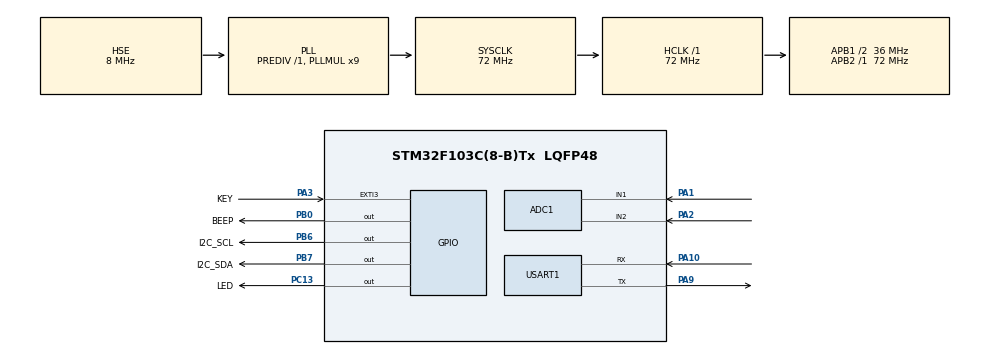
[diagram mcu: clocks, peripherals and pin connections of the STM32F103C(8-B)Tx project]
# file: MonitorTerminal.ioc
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ADC1.Channel-4\#ChannelRegularConversion=ADC_CHANNEL_1
ADC1.Channel-5\#ChannelRegularConversion=ADC_CHANNEL_2
ADC1.ContinuousConvMode=ENABLE
ADC1.DataAlign=ADC_DATAALIGN_RIGHT
ADC1.DiscontinuousConvMode=DISABLE
ADC1.NbrOfConversion=2
ADC1.NbrOfConversionFlag=1
ADC1.Rank-4\#ChannelRegularConversion=1
ADC1.Rank-5\#ChannelRegularConversion=2
ADC1.SamplingTime-4\#ChannelRegularConversion=ADC_SAMPLETIME_55CYCLES_5
ADC1.SamplingTime-5\#ChannelRegularConversion=ADC_SAMPLETIME_55CYCLES_5
ADC1.master=1
Dma.ADC1.1.Direction=DMA_PERIPH_TO_MEMORY
Dma.ADC1.1.Instance=DMA1_Channel1
Dma.ADC1.1.MemDataAlignment=DMA_MDATAALIGN_HALFWORD
Dma.ADC1.1.MemInc=DMA_MINC_ENABLE
Dma.ADC1.1.Mode=DMA_CIRCULAR
Dma.ADC1.1.PeriphDataAlignment=DMA_PDATAALIGN_HALFWORD
Dma.ADC1.1.PeriphInc=DMA_PINC_DISABLE
Dma.ADC1.1.Priority=DMA_PRIORITY_LOW
Dma.Request0=USART1_TX
Dma.Request1=ADC1
Dma.USART1_TX.0.Direction=DMA_MEMORY_TO_PERIPH
Dma.USART1_TX.0.Instance=DMA1_Channel4
Dma.USART1_TX.0.MemDataAlignment=DMA_MDATAALIGN_BYTE
Dma.USART1_TX.0.MemInc=DMA_MINC_ENABLE
Dma.USART1_TX.0.Mode=DMA_NORMAL
Dma.USART1_TX.0.PeriphDataAlignment=DMA_PDATAALIGN_BYTE
Dma.USART1_TX.0.PeriphInc=DMA_PINC_DISABLE
Dma.USART1_TX.0.Priority=DMA_PRIORITY_LOW
FREERTOS.configTOTAL_HEAP_SIZE=10240
IWDG.Prescaler=IWDG_PRESCALER_64
IWDG.Reload=1249
Mcu.Family=STM32F1
Mcu.Name=STM32F103C(8-B)Tx
Mcu.Package=LQFP48
NVIC.DMA1_Channel1_IRQn=true\:5\:0\:true\:false\:true\:true\:false\:true\:true
NVIC.DMA1_Channel4_IRQn=true\:5\:0\:true\:false\:true\:true\:false\:true\:true
NVIC.EXTI3_IRQn=true\:5\:0\:true\:false\:true\:true\:false\:true\:true
NVIC.PriorityGroup=NVIC_PRIORITYGROUP_4
NVIC.TIM4_IRQn=true\:0\:0\:false\:false\:true\:false\:false\:true\:true
NVIC.TimeBase=TIM4_IRQn
NVIC.TimeBaseIP=TIM4
NVIC.USART1_IRQn=true\:5\:0\:true\:false\:true\:true\:false\:true\:true
PA1.Signal=ADCx_IN1
PA10.Mode=Asynchronous
PA10.Signal=USART1_RX
PA13.Mode=Serial_Wire
PA13.Signal=SYS_JTMS-SWDIO
PA14.Mode=Serial_Wire
PA14.Signal=SYS_JTCK-SWCLK
PA2.Signal=ADCx_IN2
PA3.GPIO_Label=KEY
PA3.GPIO_ModeDefaultEXTI=GPIO_MODE_IT_FALLING
PA3.GPIO_PuPd=GPIO_PULLUP
PA3.Signal=GPXTI3
PA9.Mode=Asynchronous
PA9.Signal=USART1_TX
PB0.GPIO_Label=BEEP
PB0.Signal=GPIO_Output
PB6.GPIO_Label=I2C_SCL
PB6.GPIO_ModeDefaultOutputPP=GPIO_MODE_OUTPUT_OD
PB6.GPIO_PuPd=GPIO_PULLUP
PB6.GPIO_Speed=GPIO_SPEED_FREQ_HIGH
PB6.PinState=GPIO_PIN_SET
PB6.Signal=GPIO_Output
PB7.GPIO_Label=I2C_SDA
PB7.GPIO_ModeDefaultOutputPP=GPIO_MODE_OUTPUT_OD
PB7.GPIO_PuPd=GPIO_PULLUP
PB7.GPIO_Speed=GPIO_SPEED_FREQ_HIGH
PB7.PinState=GPIO_PIN_SET
PB7.Signal=GPIO_Output
PC13-TAMPER-RTC.GPIO_Label=LED
PC13-TAMPER-RTC.PinState=GPIO_PIN_SET
PC13-TAMPER-RTC.Signal=GPIO_Output
PD0-OSC_IN.Mode=HSE-External-Oscillator
PD0-OSC_IN.Signal=RCC_OSC_IN
PD1-OSC_OUT.Mode=HSE-External-Oscillator
PD1-OSC_OUT.Signal=RCC_OSC_OUT
ProjectManager.HeapSize=0x200
ProjectManager.StackSize=0x400
ProjectManager.TargetToolchain=MDK-ARM V5
RCC.ADCPresc=RCC_ADCPCLK2_DIV6
RCC.AHBFreq_Value=72000000
RCC.APB1CLKDivider=RCC_HCLK_DIV2
RCC.APB1Freq_Value=36000000
RCC.APB1TimFreq_Value=72000000
RCC.APB2Freq_Value=72000000
RCC.APB2TimFreq_Value=72000000
RCC.HCLKFreq_Value=72000000
RCC.PLLMUL=RCC_PLL_MUL9
RCC.PLLSourceVirtual=RCC_PLLSOURCE_HSE
RCC.SYSCLKFreq_VALUE=72000000
RCC.SYSCLKSource=RCC_SYSCLKSOURCE_PLLCLK
RCC.USBFreq_Value=72000000
SH.ADCx_IN1.0=ADC1_IN1,IN1
SH.ADCx_IN2.0=ADC1_IN2,IN2
USART1.VirtualMode=VM_ASYNC
VP_FREERTOS_VS_CMSIS_V2.Mode=CMSIS_V2
VP_IWDG_VS_IWDG.Mode=IWDG_Activate
VP_SYS_VS_tim4.Mode=TIM4
board=custom

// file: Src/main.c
/* USER CODE BEGIN Header */
/**
  ******************************************************************************
  * @file           : main.c
  * @brief          : Main program body
  ******************************************************************************
  * @attention
  *
  * <h2><center>&copy; Copyright (c) 2026 STMicroelectronics.
  * All rights reserved.</center></h2>
  *
  * This software component is licensed by ST under BSD 3-Clause license,
  * the "License"; You may not use this file except in compliance with the
  * License. You may obtain a copy of the License at:
  *                        opensource.org/licenses/BSD-3-Clause
  *
  ******************************************************************************
  */
/* USER CODE END Header */
#include "main.h"
#include "cmsis_os.h"
#include "adc.h"
#include "dma.h"
#include "iwdg.h"
#include "usart.h"
#include "gpio.h"

void SystemClock_Config(void);
void MX_FREERTOS_Init(void);

int main(void)
{

  /* MCU Configuration--------------------------------------------------------*/

  /* Reset of all peripherals, Initializes the Flash interface and the Systick. */
  HAL_Init();

  /* Configure the system clock */
  SystemClock_Config();

  /* Initialize all configured peripherals */
  MX_GPIO_Init();
  MX_DMA_Init();
  MX_USART1_UART_Init();
  MX_ADC1_Init();
  MX_IWDG_Init();
  /* USER CODE BEGIN 2 */
  /* 这里不要再调 osKernelInitialize()：下面 CubeMX 生成的那一行已经调过了。
     第二次调用时 KernelState 已是 osKernelReady，cmsis_os2.c 会直接返回
     osError（返回值没人接，所以无害，但属于多余代码）。 */

  /* USER CODE END 2 */

  /* Init scheduler */
  osKernelInitialize();  /* Call init function for freertos objects (in cmsis_os2.c) */
  MX_FREERTOS_Init();

  /* Start scheduler */
  osKernelStart();

  /* We should never get here as control is now taken by the scheduler */

  /* Infinite loop */
  /* USER CODE BEGIN WHILE */
  while (1)
  {
    /* PC13 板载 LED 低电平点亮，翻转一次即改变亮灭状态 */
    HAL_GPIO_TogglePin(LED_GPIO_Port, LED_Pin);
    /* �? 0.5s + �? 0.5s = 1Hz */
    HAL_Delay(500);
    /* USER CODE END WHILE */

  }
}

void SystemClock_Config(void)
{
  RCC_OscInitTypeDef RCC_OscInitStruct = {0};
  RCC_ClkInitTypeDef RCC_ClkInitStruct = {0};
  RCC_PeriphCLKInitTypeDef PeriphClkInit = {0};

  /** Initializes the RCC Oscillators according to the specified parameters
  * in the RCC_OscInitTypeDef structure.
  */
  RCC_OscInitStruct.OscillatorType = RCC_OSCILLATORTYPE_LSI|RCC_OSCILLATORTYPE_HSE;
  RCC_OscInitStruct.HSEState = RCC_HSE_ON;
  RCC_OscInitStruct.HSEPredivValue = RCC_HSE_PREDIV_DIV1;
  RCC_OscInitStruct.HSIState = RCC_HSI_ON;
  RCC_OscInitStruct.LSIState = RCC_LSI_ON;
  RCC_OscInitStruct.PLL.PLLState = RCC_PLL_ON;
  RCC_OscInitStruct.PLL.PLLSource = RCC_PLLSOURCE_HSE;
  RCC_OscInitStruct.PLL.PLLMUL = RCC_PLL_MUL9;
  if (HAL_RCC_OscConfig(&RCC_OscInitStruct) != HAL_OK)
  {
    Error_Handler();
  }

  /** Initializes the CPU, AHB and APB buses clocks
  */
  RCC_ClkInitStruct.ClockType = RCC_CLOCKTYPE_HCLK|RCC_CLOCKTYPE_SYSCLK
                              |RCC_CLOCKTYPE_PCLK1|RCC_CLOCKTYPE_PCLK2;
  RCC_ClkInitStruct.SYSCLKSource = RCC_SYSCLKSOURCE_PLLCLK;
  RCC_ClkInitStruct.AHBCLKDivider = RCC_SYSCLK_DIV1;
  RCC_ClkInitStruct.APB1CLKDivider = RCC_HCLK_DIV2;
  RCC_ClkInitStruct.APB2CLKDivider = RCC_HCLK_DIV1;

  if (HAL_RCC_ClockConfig(&RCC_ClkInitStruct, FLASH_LATENCY_2) != HAL_OK)
  {
    Error_Handler();
  }
  PeriphClkInit.PeriphClockSelection = RCC_PERIPHCLK_ADC;
  PeriphClkInit.AdcClockSelection = RCC_ADCPCLK2_DIV6;
  if (HAL_RCCEx_PeriphCLKConfig(&PeriphClkInit) != HAL_OK)
  {
    Error_Handler();
  }
}

void HAL_TIM_PeriodElapsedCallback(TIM_HandleTypeDef *htim)
{
  if (htim->Instance == TIM4)
  {
    HAL_IncTick();
  }
}

void Error_Handler(void)
{
  /* USER CODE BEGIN Error_Handler_Debug */
  /* 让"初始化失败"变成肉眼可见的信号 —— 而不是停在一个死的死循环里。
   *
   * 为什么必须做这件事：app_ssd1306.c 的 ssd1306_init() 在 I²C 事务失败时
   * 会调本函数。CubeMX 生成的默认实现是 `__disable_irq(); while(1){}`，
   * 板上**没有任何提示**，看上去和"程序根本没跑起来"一模一样。
   * 护栏设了却不接线，等于没设。
   *
   * 为什么先 __disable_irq()：
   *   本函数可能是从 TaskDisplay（最低优先级）里调用的，而 TaskAcquire
   *   每秒也在翻转**同一颗** PC13（调度器心跳）。不关中断两处翻转会互相
   *   打架，看到的是混合节奏，信号就废了。
   *   关掉中断 → SysTick 停 → 调度器停 → 只剩这里在闪，信号干净。
   *
   * 现象对照：
   *   PC13 约 1 秒一闪  = 正常（调度器心跳，本函数没被调用）
   *   PC13 飞快地闪     = 本函数被调用 = 初始化失败 */
  __disable_irq();

  for (;;)
  {
    volatile uint32_t i;

    HAL_GPIO_TogglePin(LED_GPIO_Port, LED_Pin);

    /* 约 500000 × 6 周期 / 72MHz ≈ 42ms → 约 12Hz 的快闪 */
    for (i = 0u; i < 500000u; i++)
    {
      __NOP();
    }
  }
  /* USER CODE END Error_Handler_Debug */
}

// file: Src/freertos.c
/* USER CODE BEGIN Header */
/**
  ******************************************************************************
  * File Name          : freertos.c
  * Description        : Code for freertos applications
  ******************************************************************************
  * @attention
  *
  * <h2><center>&copy; Copyright (c) 2026 STMicroelectronics.
  * All rights reserved.</center></h2>
  *
  * This software component is licensed by ST under Ultimate Liberty license
  * SLA0044, the "License"; You may not use this file except in compliance with
  * the License. You may obtain a copy of the License at:
  *                             www.st.com/SLA0044
  *
  ******************************************************************************
  */
/* USER CODE END Header */

#include "FreeRTOS.h"
#include "task.h"
#include "main.h"
#include "cmsis_os.h"

/* USER CODE BEGIN Includes */
#include "app_tasks.h"

/* USER CODE END Includes */

void MX_FREERTOS_Init(void); /* (MISRA C 2004 rule 8.1) */

void MX_FREERTOS_Init(void) {

  /* USER CODE BEGIN RTOS_THREADS */

  /* 创建队列 / 事件组 / 互斥锁，并创建六个任务（实现见 App/app_tasks.c） */
  app_init();

  /* ★ 这里为什么没有 CubeMX 生成的 defaultTask：
   *
   *   CubeMX 的 FreeRTOS 配置里默认带一个 defaultTask，内容只有
   *       for(;;) { osDelay(1); }
   *   一个空循环。六个真正的任务全部由上面的 app_init() 创建，它不起任何作用，
   *   却要占一个任务槽和 512 字节栈（本工程 RAM 一共才 20KB）。
   *
   *   所以它已经从 .ioc 的 FreeRTOS 任务列表里一并删掉了
   *   （见 .ioc 的 FREERTOS.IPParameters，里面只剩 configTOTAL_HEAP_SIZE），
   *   CubeMX 重新生成时不会再产生它。
   *
   *   ⚠️ 这里踩过一次：早期是手工删代码、.ioc 里还留着它，于是 2026-09-21 用
   *      CubeMX 6.18.1 原生 V2 重新生成之后它又悄悄回来了，还带着一段写着
   *      「已删掉」的注释。代码和 .ioc 两边一起改才是干净的。 */

  /* add threads, ... */
  /* USER CODE END RTOS_THREADS */

}
